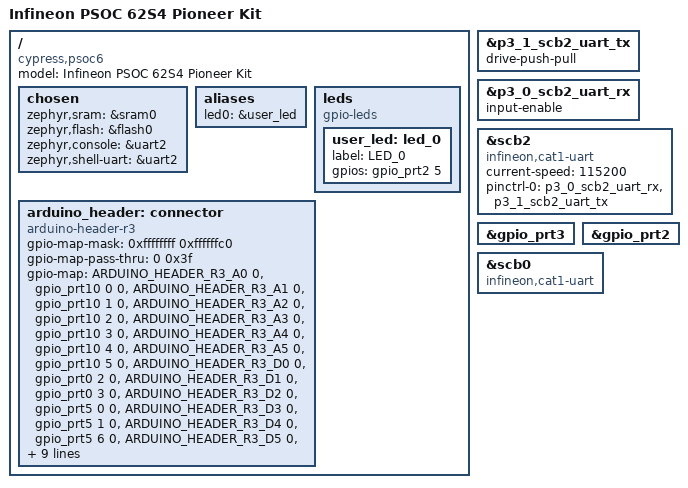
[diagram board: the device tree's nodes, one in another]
/*
 * Copyright (c) 2024 David Ullmann
 * SPDX-License-Identifier: Apache-2.0
 */

/dts-v1/;
#include <infineon/cat1a/mpns/CY8C6244LQI_S4D92.dtsi>
#include <zephyr/dt-bindings/gpio/arduino-header-r3.h>

/ {
	model = "Infineon PSOC 62S4 Pioneer Kit";
	compatible ="cypress,psoc6";
	chosen {
		zephyr,sram = &sram0;
		zephyr,flash = &flash0;
		zephyr,console = &uart2;
		zephyr,shell-uart = &uart2;
	};

	aliases {
		led0 = &user_led;
	};

	leds {
		compatible = "gpio-leds";
		user_led: led_0 {
			label = "LED_0";
			gpios = <&gpio_prt2 5 GPIO_ACTIVE_HIGH>;
		};

	};

	arduino_header: connector {
		compatible = "arduino-header-r3";
		#gpio-cells = <2>;
		gpio-map-mask = <0xffffffff 0xffffffc0>;
		gpio-map-pass-thru = <0 0x3f>;		/* shared */
		gpio-map = <ARDUINO_HEADER_R3_A0 0 &gpio_prt10 0 0>,
			   <ARDUINO_HEADER_R3_A1 0 &gpio_prt10 1 0>,
			   <ARDUINO_HEADER_R3_A2 0 &gpio_prt10 2 0>,
			   <ARDUINO_HEADER_R3_A3 0 &gpio_prt10 3 0>,
			   <ARDUINO_HEADER_R3_A4 0 &gpio_prt10 4 0>,
			   <ARDUINO_HEADER_R3_A5 0 &gpio_prt10 5 0>,
			   <ARDUINO_HEADER_R3_D0 0 &gpio_prt0 2 0>,	/* RX-5 */
			   <ARDUINO_HEADER_R3_D1 0 &gpio_prt0 3 0>,	/* TX-5 */
			   <ARDUINO_HEADER_R3_D2 0 &gpio_prt5 0 0>,	/* RTS-5 */
			   <ARDUINO_HEADER_R3_D3 0 &gpio_prt5 1 0>,	/* CTS-5 */
			   <ARDUINO_HEADER_R3_D4 0 &gpio_prt5 6 0>,
			   <ARDUINO_HEADER_R3_D5 0 &gpio_prt5 7 0>,
			   <ARDUINO_HEADER_R3_D6 0 &gpio_prt6 2 0>,
			   <ARDUINO_HEADER_R3_D7 0 &gpio_prt6 3 0>,
			   <ARDUINO_HEADER_R3_D8 0 &gpio_prt2 4 0>,	/* RX-6 */
			   <ARDUINO_HEADER_R3_D9 0 &gpio_prt2 6 0>,	/* TX-6 */
			   <ARDUINO_HEADER_R3_D10 0 &gpio_prt2 3 0>,
			   <ARDUINO_HEADER_R3_D11 0 &gpio_prt2 0 0>,
			   <ARDUINO_HEADER_R3_D12 0 &gpio_prt2 1 0>,
			   <ARDUINO_HEADER_R3_D13 0 &gpio_prt2 2 0>;
	};
};

&p3_1_scb2_uart_tx {
	drive-push-pull;
};

&p3_0_scb2_uart_rx {
	input-enable;
};


uart2: &scb2 {
	compatible = "infineon,cat1-uart";
	status = "okay";
	current-speed = <115200>;
	pinctrl-0 = <&p3_0_scb2_uart_rx &p3_1_scb2_uart_tx>;
	pinctrl-names = "default";
};

&gpio_prt3 {
	status = "okay";
};

&gpio_prt2 {
	status = "okay";
};

uart0: &scb0 {
	compatible = "infineon,cat1-uart";
};

arduino_serial: &uart0 {};
